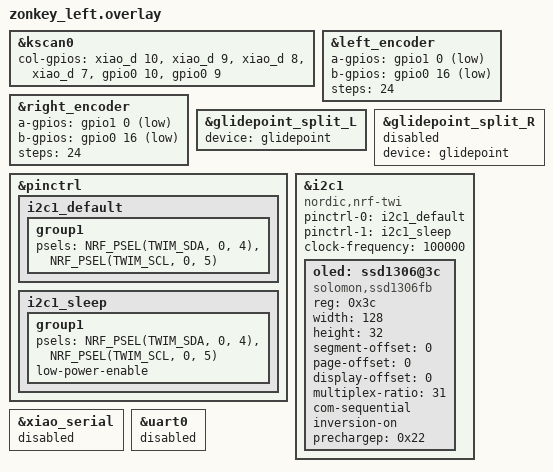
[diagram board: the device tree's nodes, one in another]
#include "zonkey.dtsi"

&kscan0 {
        col-gpios
            = <&xiao_d 10 GPIO_ACTIVE_HIGH>
            , <&xiao_d 9 GPIO_ACTIVE_HIGH> 
            , <&xiao_d 8 GPIO_ACTIVE_HIGH> 
            , <&xiao_d 7 GPIO_ACTIVE_HIGH> 
            , <&gpio0 10 GPIO_ACTIVE_HIGH>
            , <&gpio0 9 GPIO_ACTIVE_HIGH>
            ;
};

&left_encoder {
    a-gpios = <&gpio1  0 (GPIO_ACTIVE_LOW | GPIO_PULL_UP)>;
    b-gpios = <&gpio0 16 (GPIO_ACTIVE_LOW | GPIO_PULL_UP)>;
    steps = <24>;
    status = "okay";
};

&right_encoder {
    a-gpios = <&gpio1  0 (GPIO_ACTIVE_LOW | GPIO_PULL_UP)>;
    b-gpios = <&gpio0 16 (GPIO_ACTIVE_LOW | GPIO_PULL_UP)>;
    steps = <24>;
    status = "okay";
};

&glidepoint_split_L {
    status = "okay";
    device = <&glidepoint>;
};
&glidepoint_split_R {
    status = "disabled";
    device = <&glidepoint>;
};
// I2C設定 (OLED用)
&pinctrl {
    i2c1_default: i2c1_default {
        group1 {
            psels = <NRF_PSEL(TWIM_SDA, 0, 4)>,
                    <NRF_PSEL(TWIM_SCL, 0, 5)>;
        };
    };

    i2c1_sleep: i2c1_sleep {
        group1 {
            psels = <NRF_PSEL(TWIM_SDA, 0, 4)>,
                    <NRF_PSEL(TWIM_SCL, 0, 5)>;
            low-power-enable;
        };
    };
};

&i2c1 {
    status = "okay";
    compatible = "nordic,nrf-twi";
    pinctrl-0 = <&i2c1_default>;
    pinctrl-1 = <&i2c1_sleep>;
    pinctrl-names = "default", "sleep";

    clock-frequency = <100000>;
    oled: ssd1306@3c {
        compatible = "solomon,ssd1306fb";
        reg = <0x3c>;
        width = <128>;
        height = <32>;
        segment-offset = <0>;
        page-offset = <0>;
        display-offset = <0>;
        multiplex-ratio = <31>;
        com-sequential;
        inversion-on;
        prechargep = <0x22>;
    };
};

&xiao_serial { status = "disabled"; };
&uart0 { status = "disabled";};
